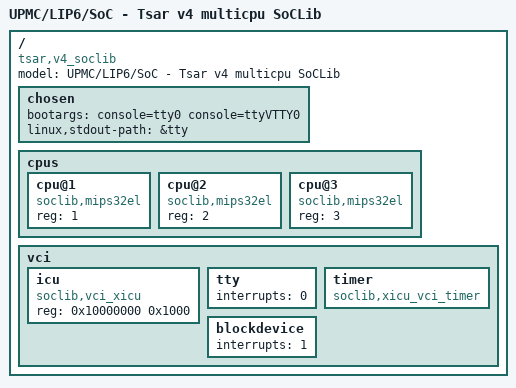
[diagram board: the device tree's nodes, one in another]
/*
 * DTS file for TSAR multicpu on SoCLib
 *
 * Includes the skeleton and specializes it:
 *  - add 3 cpus
 *  - use of vci_xicu (and its corresponding timers)
 */

/dts-v1/;

/include/ "tsar_soclib_skeleton.dtsi"

/ {
	model = "UPMC/LIP6/SoC - Tsar v4 multicpu SoCLib";
	compatible = "tsar,v4_soclib", "tsar,multicpu_v4_soclib";

	chosen {
		/* the day we have a uart8250 compatible component, we can use
		 * the earlycon param to get earlyprintk */
		/* bootargs = "earlycon=uart8250,mmio,0x00000000"; */

		/* this is for maximum debug */
		/* bootargs = "ignore_loglevel initcall_debug"; */

		/* display console in both framebuffer and tty (the last one
		 * becomes the default one) */
		bootargs = "console=tty0 console=ttyVTTY0";

		/* default peripheral to use when configuring earlyprintk */
		linux,stdout-path = &tty;
	};

	cpus {
		cpu@1 {
			device_type = "cpu";
			compatible = "soclib,mips32el";
			reg = <1>;
		};
		cpu@2 {
			device_type = "cpu";
			compatible = "soclib,mips32el";
			reg = <2>;
		};
		cpu@3 {
			device_type = "cpu";
			compatible = "soclib,mips32el";
			reg = <3>;
		};
	};

	vci {
		icu: icu {
			/* the vci_xicu is a N->N interrupt controller,
			 * with support for IPI */
			compatible = "soclib,vci_xicu";
			reg = <0x10000000 0x1000>;
		};

		tty: tty {
			interrupts = <0>;
		};

		timer {
			compatible = "soclib,xicu_vci_timer";
		};

		blockdevice {
			interrupts = <1>;
		};
	};
};
